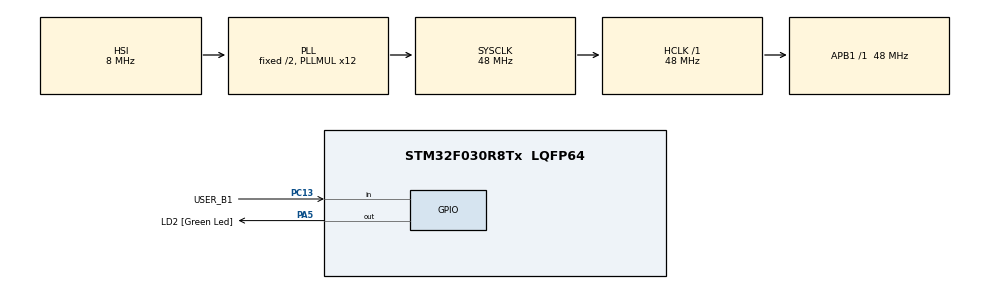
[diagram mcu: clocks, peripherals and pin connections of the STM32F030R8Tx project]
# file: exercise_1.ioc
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Mcu.Family=STM32F0
Mcu.Name=STM32F030R8Tx
Mcu.Package=LQFP64
PA5.GPIO_Label=LD2 [Green Led]
PA5.GPIO_Mode=GPIO_MODE_OUTPUT_PP
PA5.GPIO_PuPd=GPIO_NOPULL
PA5.GPIO_Speed=GPIO_SPEED_FREQ_LOW
PA5.PinState=GPIO_PIN_RESET
PA5.Signal=GPIO_Output
PC13.GPIO_Label=USER_B1
PC13.Signal=GPIO_Input
ProjectManager.HeapSize=0x200
ProjectManager.StackSize=0x400
ProjectManager.TargetToolchain=STM32CubeIDE
RCC.AHBFreq_Value=48000000
RCC.APB1Freq_Value=48000000
RCC.APB1TimFreq_Value=48000000
RCC.HCLKFreq_Value=48000000
RCC.PLLMUL=RCC_PLL_MUL12
RCC.SYSCLKFreq_VALUE=48000000
RCC.SYSCLKSource=RCC_SYSCLKSOURCE_PLLCLK
board=NUCLEO-F030R8

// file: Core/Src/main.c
/* USER CODE BEGIN Header */
/**
  ******************************************************************************
  * @file           : main.c
  * @brief          : Main program body
  ******************************************************************************
  * @attention
  *
  * Copyright (c) 2025 STMicroelectronics.
  * All rights reserved.
  *
  * This software is licensed under terms that can be found in the LICENSE file
  * in the root directory of this software component.
  * If no LICENSE file comes with this software, it is provided AS-IS.
  *
  ******************************************************************************
  */
/* USER CODE END Header */
#include "main.h"

void SystemClock_Config(void);
static void MX_GPIO_Init(void);

int main(void)
{

  /* MCU Configuration--------------------------------------------------------*/

  /* Reset of all peripherals, Initializes the Flash interface and the Systick. */
  HAL_Init();

  /* Configure the system clock */
  SystemClock_Config();

  /* Initialize all configured peripherals */
  MX_GPIO_Init();

  /* Infinite loop */
  /* USER CODE BEGIN WHILE */
  while (1)
  {
	  if(HAL_GPIO_ReadPin(USER_B1_GPIO_Port, USER_B1_Pin) == GPIO_PIN_RESET)
		  HAL_GPIO_WritePin(LD2_GPIO_Port,LD2_Pin, GPIO_PIN_SET);
	  else
		  HAL_GPIO_WritePin(LD2_GPIO_Port,LD2_Pin, GPIO_PIN_RESET);
    /* USER CODE END WHILE */

  }
}

void SystemClock_Config(void)
{
  RCC_OscInitTypeDef RCC_OscInitStruct = {0};
  RCC_ClkInitTypeDef RCC_ClkInitStruct = {0};

  /** Initializes the RCC Oscillators according to the specified parameters
  * in the RCC_OscInitTypeDef structure.
  */
  RCC_OscInitStruct.OscillatorType = RCC_OSCILLATORTYPE_HSI;
  RCC_OscInitStruct.HSIState = RCC_HSI_ON;
  RCC_OscInitStruct.HSICalibrationValue = RCC_HSICALIBRATION_DEFAULT;
  RCC_OscInitStruct.PLL.PLLState = RCC_PLL_ON;
  RCC_OscInitStruct.PLL.PLLSource = RCC_PLLSOURCE_HSI;
  RCC_OscInitStruct.PLL.PLLMUL = RCC_PLL_MUL12;
  RCC_OscInitStruct.PLL.PREDIV = RCC_PREDIV_DIV1;
  if (HAL_RCC_OscConfig(&RCC_OscInitStruct) != HAL_OK)
  {
    Error_Handler();
  }

  /** Initializes the CPU, AHB and APB buses clocks
  */
  RCC_ClkInitStruct.ClockType = RCC_CLOCKTYPE_HCLK|RCC_CLOCKTYPE_SYSCLK
                              |RCC_CLOCKTYPE_PCLK1;
  RCC_ClkInitStruct.SYSCLKSource = RCC_SYSCLKSOURCE_PLLCLK;
  RCC_ClkInitStruct.AHBCLKDivider = RCC_SYSCLK_DIV1;
  RCC_ClkInitStruct.APB1CLKDivider = RCC_HCLK_DIV1;

  if (HAL_RCC_ClockConfig(&RCC_ClkInitStruct, FLASH_LATENCY_1) != HAL_OK)
  {
    Error_Handler();
  }
}

static void MX_GPIO_Init(void)
{
  GPIO_InitTypeDef GPIO_InitStruct = {0};

  /* GPIO Ports Clock Enable */
  __HAL_RCC_GPIOC_CLK_ENABLE();
  __HAL_RCC_GPIOA_CLK_ENABLE();

  /*Configure GPIO pin Output Level */
  HAL_GPIO_WritePin(LD2_GPIO_Port, LD2_Pin, GPIO_PIN_RESET);

  /*Configure GPIO pin : USER_B1_Pin */
  GPIO_InitStruct.Pin = USER_B1_Pin;
  GPIO_InitStruct.Mode = GPIO_MODE_INPUT;
  GPIO_InitStruct.Pull = GPIO_NOPULL;
  HAL_GPIO_Init(USER_B1_GPIO_Port, &GPIO_InitStruct);

  /*Configure GPIO pin : LD2_Pin */
  GPIO_InitStruct.Pin = LD2_Pin;
  GPIO_InitStruct.Mode = GPIO_MODE_OUTPUT_PP;
  GPIO_InitStruct.Pull = GPIO_NOPULL;
  GPIO_InitStruct.Speed = GPIO_SPEED_FREQ_LOW;
  HAL_GPIO_Init(LD2_GPIO_Port, &GPIO_InitStruct);

}

void Error_Handler(void)
{
  __disable_irq();
  while (1)
  {
  }
}
